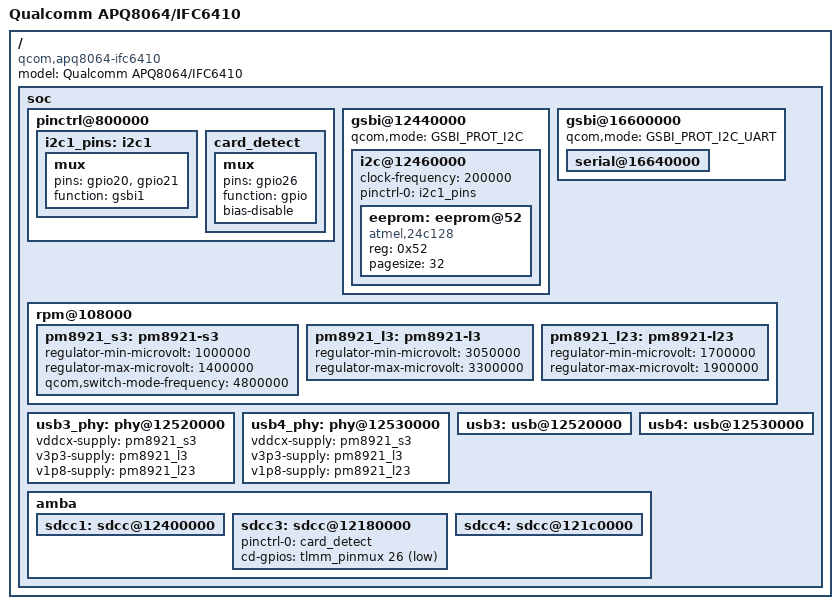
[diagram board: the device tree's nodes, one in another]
#include "qcom-apq8064-v2.0.dtsi"
#include <dt-bindings/gpio/gpio.h>

/ {
	model = "Qualcomm APQ8064/IFC6410";
	compatible = "qcom,apq8064-ifc6410", "qcom,apq8064";

	soc {
		pinctrl@800000 {
			i2c1_pins: i2c1 {
				mux {
					pins = "gpio20", "gpio21";
					function = "gsbi1";
				};
			};

			card_detect: card_detect {
				mux {
					pins = "gpio26";
					function = "gpio";
					bias-disable;
				};
			};
		};

		gsbi@12440000 {
			status = "okay";
			qcom,mode = <GSBI_PROT_I2C>;

			i2c@12460000 {
				status = "okay";
				clock-frequency = <200000>;
				pinctrl-0 = <&i2c1_pins>;
				pinctrl-names = "default";

				eeprom: eeprom@52 {
					compatible = "atmel,24c128";
					reg = <0x52>;
					pagesize = <32>;
				};
			};
		};

		gsbi@16600000 {
			status = "ok";
			qcom,mode = <GSBI_PROT_I2C_UART>;
			serial@16640000 {
				status = "ok";
			};
		};

		rpm@108000 {
			pm8921_s3: pm8921-s3 {
				regulator-min-microvolt		= <1000000>;
				regulator-max-microvolt		= <1400000>;
				qcom,switch-mode-frequency	= <4800000>;
			};

			pm8921_l3: pm8921-l3 {
				regulator-min-microvolt = <3050000>;
				regulator-max-microvolt = <3300000>;
			};

			pm8921_l23: pm8921-l23 {
				regulator-min-microvolt = <1700000>;
				regulator-max-microvolt = <1900000>;
			};
		};

		usb3_phy: phy@12520000 {
			status		= "okay";
			vddcx-supply	= <&pm8921_s3>;
			v3p3-supply	= <&pm8921_l3>;
			v1p8-supply	= <&pm8921_l23>;
		};

		usb4_phy: phy@12530000 {
			status		= "okay";
			vddcx-supply	= <&pm8921_s3>;
			v3p3-supply	= <&pm8921_l3>;
			v1p8-supply	= <&pm8921_l23>;
		};

		usb3: usb@12520000 {
			status = "okay";
		};

		usb4: usb@12530000 {
			status = "okay";
		};

		amba {
			/* eMMC */
			sdcc1: sdcc@12400000 {
				status = "okay";
			};

			/* External micro SD card */
			sdcc3: sdcc@12180000 {
				status = "okay";
				pinctrl-names	= "default";
				pinctrl-0	= <&card_detect>;
				cd-gpios	= <&tlmm_pinmux 26 GPIO_ACTIVE_LOW>;
			};
			/* WLAN */
			sdcc4: sdcc@121c0000 {
				status = "okay";
			};
		};
	};
};
